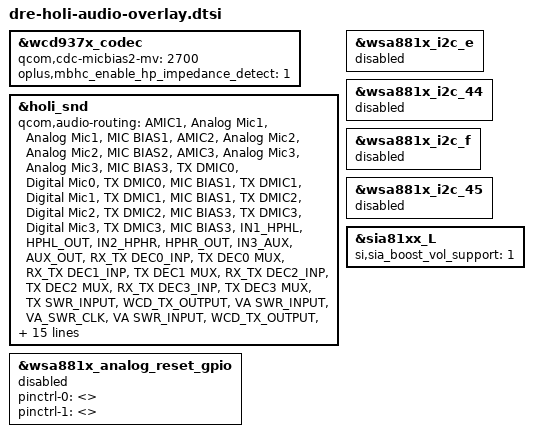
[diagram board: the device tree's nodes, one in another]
/**********************************************************************************
* Copyright (c)  2008-2019  Guangdong OPLUS Mobile Comm Corp., Ltd
* Description: OPLUS Audio Module Device Tree
*
* Version: 1.0
* Date: 2020-10-17
* Author: Le.Li
*
* ------------------------------ Revision History: --------------------------------
* <version>           <date>                <author>                            <desc>
* Revision 1.0       2020-10-17            Le.Li             Created for new architecture
***********************************************************************************/

#include "oplus-smartpa-sia81xx.dtsi"

&wcd937x_codec {
	qcom,cdc-micbias2-mv = <2700>;
	/* #ifdef OPLUS_FEATURE_IMPEDANCE_MATCH */
	oplus,mbhc_enable_hp_impedance_detect = <1>;
	/* #endif OPLUS_FEATURE_IMPEDANCE_MATCH */
};

&holi_snd {
	qcom,audio-routing =
		"AMIC1", "Analog Mic1",
		"Analog Mic1", "MIC BIAS1",
		"AMIC2", "Analog Mic2",
		"Analog Mic2", "MIC BIAS2",
		"AMIC3", "Analog Mic3",
		"Analog Mic3", "MIC BIAS3",
		"TX DMIC0", "Digital Mic0",
		"TX DMIC0", "MIC BIAS1",
		"TX DMIC1", "Digital Mic1",
		"TX DMIC1", "MIC BIAS1",
		"TX DMIC2", "Digital Mic2",
		"TX DMIC2", "MIC BIAS3",
		"TX DMIC3", "Digital Mic3",
		"TX DMIC3", "MIC BIAS3",
		"IN1_HPHL", "HPHL_OUT",
		"IN2_HPHR", "HPHR_OUT",
		"IN3_AUX", "AUX_OUT",
		"RX_TX DEC0_INP", "TX DEC0 MUX",
		"RX_TX DEC1_INP", "TX DEC1 MUX",
		"RX_TX DEC2_INP", "TX DEC2 MUX",
		"RX_TX DEC3_INP", "TX DEC3 MUX",
		"TX SWR_INPUT", "WCD_TX_OUTPUT",
		"VA SWR_INPUT", "VA_SWR_CLK",
		"VA SWR_INPUT", "WCD_TX_OUTPUT",
		"VA_AIF1 CAP", "VA_SWR_CLK",
		"VA_AIF2 CAP", "VA_SWR_CLK",
		"VA_AIF3 CAP", "VA_SWR_CLK",
		"VA DMIC0", "Digital Mic0",
		"VA DMIC1", "Digital Mic1",
		"VA DMIC2", "Digital Mic2",
		"VA DMIC3", "Digital Mic3",
		"VA DMIC4", "Digital Mic4",
		"VA DMIC5", "Digital Mic5",
		"VA DMIC0", "VA MIC BIAS1",
		"VA DMIC1", "VA MIC BIAS1",
		"VA DMIC2", "VA MIC BIAS3",
		"VA DMIC3", "VA MIC BIAS3";
	qcom,msm-mbhc-moist-cfg = <1>, <3>, <0>;
	qcom,msm-mbhc-usbc-audio-supported = <0>;
	qcom,msm-mbhc-hphl-swh = <1>;
	qcom,msm-mbhc-gnd-swh = <1>;
	qcom,msm-mbhc-hs-mic-max-threshold-mv = <2600>;
	qcom,msm-mbhc-hs-mic-min-threshold-mv = <75>;
};

&wsa881x_i2c_e {
	status = "disabled";
};

&wsa881x_i2c_44 {
	status = "disabled";
};

&wsa881x_i2c_f {
	status = "disabled";
};

&wsa881x_i2c_45 {
	status = "disabled";
};

&wsa881x_analog_reset_gpio {
	status = "disabled";
	pinctrl-0 = <>;
	pinctrl-1 = <>;
};

&sia81xx_L{
	si,sia_boost_vol_support = <1>;
};
